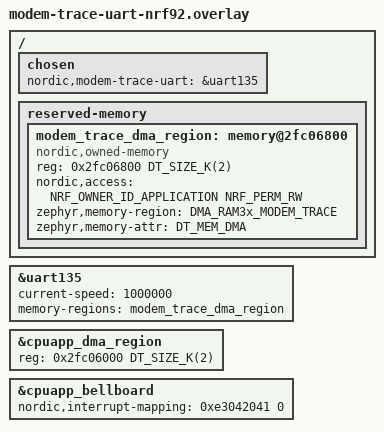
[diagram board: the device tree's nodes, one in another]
/*
 * Copyright (c) 2025 Nordic Semiconductor ASA
 *
 * SPDX-License-Identifier: LicenseRef-Nordic-5-Clause
 */

/* Enable uart135 for tracing. */
&uart135 {
	status = "okay";
	current-speed = <1000000>;
	memory-regions = <&modem_trace_dma_region>;
};

/ {
	chosen {
		nordic,modem-trace-uart = &uart135;
	};

	reserved-memory {
		/* Add memory region for tracing UART. */
		modem_trace_dma_region: memory@2fc06800 {
			compatible = "nordic,owned-memory", "zephyr,memory-region";
			reg = <0x2fc06800 DT_SIZE_K(2)>;
			status = "okay";
			#memory-region-cells = <0>;
			nordic,access = <NRF_OWNER_ID_APPLICATION NRF_PERM_RW>;
			zephyr,memory-region = "DMA_RAM3x_MODEM_TRACE";
			zephyr,memory-attr = <DT_MEM_DMA>;
		};
	};
};

/* Reduce size to make room for modem trace dma region. */
&cpuapp_dma_region {
	reg = <0x2fc06000 DT_SIZE_K(2)>;
};

/* Enable the trace signal on the application bellboard. */
&cpuapp_bellboard {
	nordic,interrupt-mapping = <0xe3042041 0>;
};
